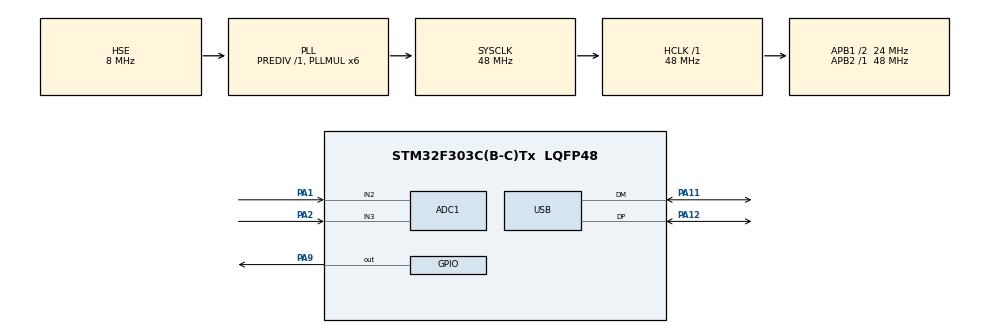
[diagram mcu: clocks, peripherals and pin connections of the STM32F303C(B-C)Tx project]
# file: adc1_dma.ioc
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ADC1.Channel-0\#ChannelRegularConversion=ADC_CHANNEL_2
ADC1.Channel-1\#ChannelRegularConversion=ADC_CHANNEL_3
ADC1.ClockPrescaler=ADC_CLOCK_ASYNC_DIV1
ADC1.DataAlign=ADC_DATAALIGN_RIGHT
ADC1.NbrOfConversion=2
ADC1.NbrOfConversionFlag=1
ADC1.Offset-0\#ChannelRegularConversion=0
ADC1.Offset-1\#ChannelRegularConversion=0
ADC1.OffsetNumber-0\#ChannelRegularConversion=ADC_OFFSET_NONE
ADC1.OffsetNumber-1\#ChannelRegularConversion=ADC_OFFSET_NONE
ADC1.Rank-0\#ChannelRegularConversion=1
ADC1.Rank-1\#ChannelRegularConversion=2
ADC1.SamplingTime-0\#ChannelRegularConversion=ADC_SAMPLETIME_61CYCLES_5
ADC1.SamplingTime-1\#ChannelRegularConversion=ADC_SAMPLETIME_61CYCLES_5
ADC1.SamplingTimeOPAMP-1\#ChannelRegularConversion=ADC_SAMPLETIME_4CYCLES_5
ADC1.master=1
Dma.ADC1.0.Direction=DMA_PERIPH_TO_MEMORY
Dma.ADC1.0.Instance=DMA1_Channel1
Dma.ADC1.0.MemDataAlignment=DMA_MDATAALIGN_HALFWORD
Dma.ADC1.0.MemInc=DMA_MINC_ENABLE
Dma.ADC1.0.Mode=DMA_CIRCULAR
Dma.ADC1.0.PeriphDataAlignment=DMA_PDATAALIGN_HALFWORD
Dma.ADC1.0.PeriphInc=DMA_PINC_DISABLE
Dma.ADC1.0.Priority=DMA_PRIORITY_LOW
Dma.Request0=ADC1
Mcu.Family=STM32F3
Mcu.Name=STM32F303C(B-C)Tx
Mcu.Package=LQFP48
NVIC.DMA1_Channel1_IRQn=true\:0\:0\:false\:false\:true\:false\:true\:true
NVIC.PriorityGroup=NVIC_PRIORITYGROUP_4
NVIC.USB_LP_CAN_RX0_IRQn=true\:0\:0\:false\:false\:true\:false\:true\:true
PA1.Mode=IN2-Single-Ended
PA1.Signal=ADC1_IN2
PA11.Mode=Device
PA11.Signal=USB_DM
PA12.Mode=Device
PA12.Signal=USB_DP
PA2.Mode=IN3-Single-Ended
PA2.Signal=ADC1_IN3
PA9.Signal=GPIO_Output
PF0-OSC_IN.Mode=HSE-External-Oscillator
PF0-OSC_IN.Signal=RCC_OSC_IN
PF1-OSC_OUT.Mode=HSE-External-Oscillator
PF1-OSC_OUT.Signal=RCC_OSC_OUT
ProjectManager.HeapSize=0x200
ProjectManager.StackSize=0x400
ProjectManager.TargetToolchain=CMake
RCC.AHBFreq_Value=48000000
RCC.APB1CLKDivider=RCC_HCLK_DIV2
RCC.APB1Freq_Value=24000000
RCC.APB1TimFreq_Value=48000000
RCC.APB2Freq_Value=48000000
RCC.APB2TimFreq_Value=48000000
RCC.CortexFreq_Value=48000000
RCC.HCLKFreq_Value=48000000
RCC.HSE_VALUE=8000000
RCC.HSI_VALUE=8000000
RCC.LSE_VALUE=32768
RCC.PLLMUL=RCC_PLL_MUL6
RCC.SYSCLKFreq_VALUE=48000000
RCC.SYSCLKSourceVirtual=RCC_SYSCLKSOURCE_PLLCLK
RCC.USBFreq_Value=48000000
USB_DEVICE.CLASS_NAME_FS=CDC
USB_DEVICE.VirtualMode=Cdc
USB_DEVICE.VirtualModeFS=Cdc_FS
VP_USB_DEVICE_VS_USB_DEVICE_CDC_FS.Mode=CDC_FS
board=custom

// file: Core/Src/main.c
/* USER CODE BEGIN Header */
/**
  ******************************************************************************
  * @file           : main.c
  * @brief          : Main program body
  ******************************************************************************
  * @attention
  *
  * Copyright (c) 2024 STMicroelectronics.
  * All rights reserved.
  *
  * This software is licensed under terms that can be found in the LICENSE file
  * in the root directory of this software component.
  * If no LICENSE file comes with this software, it is provided AS-IS.
  *
  ******************************************************************************
  */
/* USER CODE END Header */
#include "main.h"
#include "usb_device.h"

ADC_HandleTypeDef hadc1;
DMA_HandleTypeDef hdma_adc1;

void SystemClock_Config(void);
static void MX_GPIO_Init(void);
static void MX_DMA_Init(void);
static void MX_ADC1_Init(void);

int main(void)
{

  /* MCU Configuration--------------------------------------------------------*/

  /* Reset of all peripherals, Initializes the Flash interface and the Systick. */
  HAL_Init();

  /* Configure the system clock */
  SystemClock_Config();

  /* Initialize all configured peripherals */
  MX_GPIO_Init();
  MX_DMA_Init();
  MX_ADC1_Init();
  MX_USB_DEVICE_Init();
  /* USER CODE BEGIN 2 */
  HAL_GPIO_WritePin(GPIOA, GPIO_PIN_9, GPIO_PIN_SET);

  /* USER CODE END 2 */

  /* Infinite loop */
  /* USER CODE BEGIN WHILE */
  while (1)
  {
    uint8_t buffer[] = "LED BLINK\n\r";

    printf("printf send: %d, %.2f\r\n", 30, 21.5541);
    // CDC_Transmit_FS(buffer, sizeof(buffer));
    HAL_GPIO_WritePin(GPIOC, GPIO_PIN_13, GPIO_PIN_SET);
    HAL_Delay(400);
    HAL_GPIO_WritePin(GPIOC, GPIO_PIN_13, GPIO_PIN_RESET);
    HAL_Delay(400);
    /* USER CODE END WHILE */

  }
}

void SystemClock_Config(void)
{
  RCC_OscInitTypeDef RCC_OscInitStruct = {0};
  RCC_ClkInitTypeDef RCC_ClkInitStruct = {0};
  RCC_PeriphCLKInitTypeDef PeriphClkInit = {0};

  /** Initializes the RCC Oscillators according to the specified parameters
  * in the RCC_OscInitTypeDef structure.
  */
  RCC_OscInitStruct.OscillatorType = RCC_OSCILLATORTYPE_HSE;
  RCC_OscInitStruct.HSEState = RCC_HSE_ON;
  RCC_OscInitStruct.HSEPredivValue = RCC_HSE_PREDIV_DIV1;
  RCC_OscInitStruct.HSIState = RCC_HSI_ON;
  RCC_OscInitStruct.PLL.PLLState = RCC_PLL_ON;
  RCC_OscInitStruct.PLL.PLLSource = RCC_PLLSOURCE_HSE;
  RCC_OscInitStruct.PLL.PLLMUL = RCC_PLL_MUL6;
  if (HAL_RCC_OscConfig(&RCC_OscInitStruct) != HAL_OK)
  {
    Error_Handler();
  }

  /** Initializes the CPU, AHB and APB buses clocks
  */
  RCC_ClkInitStruct.ClockType = RCC_CLOCKTYPE_HCLK|RCC_CLOCKTYPE_SYSCLK
                              |RCC_CLOCKTYPE_PCLK1|RCC_CLOCKTYPE_PCLK2;
  RCC_ClkInitStruct.SYSCLKSource = RCC_SYSCLKSOURCE_PLLCLK;
  RCC_ClkInitStruct.AHBCLKDivider = RCC_SYSCLK_DIV1;
  RCC_ClkInitStruct.APB1CLKDivider = RCC_HCLK_DIV2;
  RCC_ClkInitStruct.APB2CLKDivider = RCC_HCLK_DIV1;

  if (HAL_RCC_ClockConfig(&RCC_ClkInitStruct, FLASH_LATENCY_1) != HAL_OK)
  {
    Error_Handler();
  }
  PeriphClkInit.PeriphClockSelection = RCC_PERIPHCLK_USB|RCC_PERIPHCLK_ADC12;
  PeriphClkInit.Adc12ClockSelection = RCC_ADC12PLLCLK_DIV1;
  PeriphClkInit.USBClockSelection = RCC_USBCLKSOURCE_PLL;
  if (HAL_RCCEx_PeriphCLKConfig(&PeriphClkInit) != HAL_OK)
  {
    Error_Handler();
  }
}

static void MX_ADC1_Init(void)
{

  ADC_MultiModeTypeDef multimode = {0};
  ADC_ChannelConfTypeDef sConfig = {0};

  /** Common config
  */
  hadc1.Instance = ADC1;
  hadc1.Init.ClockPrescaler = ADC_CLOCK_ASYNC_DIV1;
  hadc1.Init.Resolution = ADC_RESOLUTION_12B;
  hadc1.Init.ScanConvMode = ADC_SCAN_ENABLE;
  hadc1.Init.ContinuousConvMode = DISABLE;
  hadc1.Init.DiscontinuousConvMode = DISABLE;
  hadc1.Init.ExternalTrigConvEdge = ADC_EXTERNALTRIGCONVEDGE_NONE;
  hadc1.Init.ExternalTrigConv = ADC_SOFTWARE_START;
  hadc1.Init.DataAlign = ADC_DATAALIGN_RIGHT;
  hadc1.Init.NbrOfConversion = 2;
  hadc1.Init.DMAContinuousRequests = DISABLE;
  hadc1.Init.EOCSelection = ADC_EOC_SINGLE_CONV;
  hadc1.Init.LowPowerAutoWait = DISABLE;
  hadc1.Init.Overrun = ADC_OVR_DATA_OVERWRITTEN;
  if (HAL_ADC_Init(&hadc1) != HAL_OK)
  {
    Error_Handler();
  }

  /** Configure the ADC multi-mode
  */
  multimode.Mode = ADC_MODE_INDEPENDENT;
  if (HAL_ADCEx_MultiModeConfigChannel(&hadc1, &multimode) != HAL_OK)
  {
    Error_Handler();
  }

  /** Configure Regular Channel
  */
  sConfig.Channel = ADC_CHANNEL_2;
  sConfig.Rank = ADC_REGULAR_RANK_1;
  sConfig.SingleDiff = ADC_SINGLE_ENDED;
  sConfig.SamplingTime = ADC_SAMPLETIME_61CYCLES_5;
  sConfig.OffsetNumber = ADC_OFFSET_NONE;
  sConfig.Offset = 0;
  if (HAL_ADC_ConfigChannel(&hadc1, &sConfig) != HAL_OK)
  {
    Error_Handler();
  }

  /** Configure Regular Channel
  */
  sConfig.Channel = ADC_CHANNEL_3;
  sConfig.Rank = ADC_REGULAR_RANK_2;
  if (HAL_ADC_ConfigChannel(&hadc1, &sConfig) != HAL_OK)
  {
    Error_Handler();
  }

}

static void MX_DMA_Init(void)
{

  /* DMA controller clock enable */
  __HAL_RCC_DMA1_CLK_ENABLE();

  /* DMA interrupt init */
  /* DMA1_Channel1_IRQn interrupt configuration */
  HAL_NVIC_SetPriority(DMA1_Channel1_IRQn, 0, 0);
  HAL_NVIC_EnableIRQ(DMA1_Channel1_IRQn);

}

static void MX_GPIO_Init(void)
{
  GPIO_InitTypeDef GPIO_InitStruct = {0};

  /* GPIO Ports Clock Enable */
  __HAL_RCC_GPIOF_CLK_ENABLE();
  __HAL_RCC_GPIOA_CLK_ENABLE();

  /*Configure GPIO pin Output Level */
  HAL_GPIO_WritePin(GPIOA, GPIO_PIN_9, GPIO_PIN_RESET);

  /*Configure GPIO pin : PA9 */
  GPIO_InitStruct.Pin = GPIO_PIN_9;
  GPIO_InitStruct.Mode = GPIO_MODE_OUTPUT_PP;
  GPIO_InitStruct.Pull = GPIO_NOPULL;
  GPIO_InitStruct.Speed = GPIO_SPEED_FREQ_LOW;
  HAL_GPIO_Init(GPIOA, &GPIO_InitStruct);

}

void Error_Handler(void)
{
  __disable_irq();
  while (1)
  {
  }
}
